# BlueNRG2 register map
Vendor: STMicroelectronics; Series: BlueNRG2; File version: 1.2.1
ARM 32-bit Cortex-M0 Microcontroller based device, CPU clock up to 32MHz
CPU: CM0 r0p0, little endian, no MPU, no FPU, 2 interrupt priority bits
Registers are 32-bit, read-write, reset 0x0 unless marked. A register's access mark holds for its fields unless they carry their own. Offsets are from the block's base; lines under a group give offsets from that group; [hi:lo] are bit positions; {n}, {i} and the like mark numbered series; 'fields as' and 'values as' point back to an identical list; <NAME> marks a mode.

## Memory map
0x10000000 ROM_INFO size 0x800 — ROM information
0x40000000 GPIO size 0x1000 — GPIO Controller
0x40100000 FLASH size 0x1000 — Flash Controller
0x40200000 SYSTEM_CTRL size 0x1000 — System controller
0x40300000 UART size 0x1000
0x40400000 SPI size 0x1000 — Serial peripheral interface
0x40700000 WDG size 0x1000 — Watchdog
0x40800000 ADC size 0x1000
0x40900000 CKGEN_SOC size 0x1000 — Clock Gen SOC
0x40A00000 I2C2 size 0x1000
0x40B00000 I2C1 size 0x1000
0x40C00000 AHBUPCONV size 0x1000 — AHB up/down converter converter
0x40D00000 MFT1 size 0x1000
0x40E00000 MFT2 size 0x1000
0x40F00000 RTC size 0x1000 — Real-Time Counter
0x48000000 BLUE_CTRL size 0x1000 — BLUE Controller
0x48100000 CKGEN_BLE size 0x1000 — Clock Gen BLE
0xA0000000 DMA size 0x8
0xA0000008 DMA_CH0 size 0x10 — DMA channel
0xA000001C DMA_CH1 size 0x10
0xA0000030 DMA_CH2 size 0x10
0xA0000044 DMA_CH3 size 0x10
0xA0000058 DMA_CH4 size 0x10
0xA000006C DMA_CH5 size 0x10
0xA0000080 DMA_CH6 size 0x10
0xA0000094 DMA_CH7 size 0x10
0xB0000000 RNG size 0x1000
0xC0000000 PKA size 0x1000

## Interrupts
0 GPIO — GPIO bus interrupt
1 NVM (FLASH) — Non-volatile memory (Flash) controller interrupt
4 UART — UART interrupt
5 SPI — SPI interrupt
6 BLUE_CTRL — BLUE controller interrupt
7 WDG — Watchdog interrupt
13 ADC — ADC interrupt
14 I2C2 — I2C 2 interrupt
15 I2C1 — I2C 1 interrupt
17 MFT1A (MFT1) — Multi functional timer MFT1 interrupt A
18 MFT1B (MFT1) — Multi functional timer MFT1 interrupt B
19 MFT2A (MFT2) — Multi functional timer MFT2 interrupt A
20 MFT2B (MFT2) — Multi functional timer MFT2 interrupt B
21 RTC — RTC interrupt
22 PKA — PKA interrupt
23 DMA — DMA interrupt

## FLASH — Flash Controller
Base 0x40100000
0x00 COMMAND 16-bit — Commands for the module
0x04 CONFIG 16-bit — Configure the wrapper
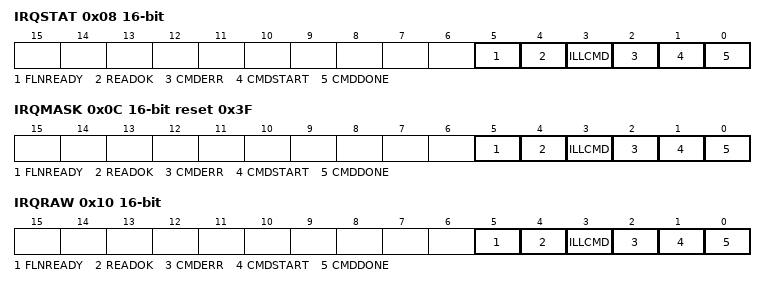
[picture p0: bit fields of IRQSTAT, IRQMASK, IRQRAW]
0x08 IRQSTAT 16-bit — Flash status interrupt (masked)
  [all] fields
    1=IRQ_PENDING; 0=IRQ_NOT_PENDING
  [5] FLNREADY — Flash not ready (sleep). 1: clear the interrupt pending bit.
  [4] READOK — Mass read was OK. 1: clear the interrupt pending bit.
  [3] ILLCMD — Illegal command written. 1: clear the interrupt pending bit.
  [2] CMDERR — Command written while BUSY. 1: clear the interrupt pending bit.
  [1] CMDSTART — Command is started. 1: clear the interrupt pending bit.
  [0] CMDDONE — Command is done. 1: clear the interrupt pending bit.
0x0C IRQMASK 16-bit reset 0x3F — Mask for interrupts
  [all] fields
    1=IRQ_PENDING; 0=IRQ_NOT_PENDING
  [5] FLNREADY — Flash not ready (sleep).
  [4] READOK — Mass read was OK.
  [3] ILLCMD — Illegal command written
  [2] CMDERR — Command written while BUSY
  [1] CMDSTART — Command is started.
  [0] CMDDONE — Command is done.
0x10 IRQRAW 16-bit — Status interrupts (unmasked)
  fields as IRQMASK
0x14 SIZE 16-bit ro — Indicates the size of the main Flash
0x18 ADDRESS — Address for programming Flash, will auto-increment
{0x40+4i} DATA{i} reset 0xFFFFFFFF (i=0..3) — Program cycle data

## Licence text in the file
THIS SOFTWARE IS PROVIDED BY THE COPYRIGHT HOLDERS AND CONTRIBUTORS "AS IS" AND ANY EXPRESS OR IMPLIED WARRANTIES, INCLUDING, BUT NOT LIMITED TO, THE IMPLIED WARRANTIES OF MERCHANTABILITY AND FITNESS FOR A PARTICULAR PURPOSE ARE DISCLAIMED. IN NO EVENT SHALL THE COPYRIGHT HOLDER OR CONTRIBUTORS BE LIABLE FOR ANY DIRECT, INDIRECT, INCIDENTAL, SPECIAL, EXEMPLARY, OR CONSEQUENTIAL DAMAGES (INCLUDING, BUT NOT LIMITED TO, PROCUREMENT OF SUBSTITUTE GOODS OR SERVICES; LOSS OF USE, DATA, OR PROFITS; OR BUSINESS INTERRUPTION) HOWEVER CAUSED AND ON ANY THEORY OF LIABILITY, WHETHER IN CONTRACT, STRICT LIABILITY, OR TORT (INCLUDING NEGLIGENCE OR OTHERWISE) ARISING IN ANY WAY OUT OF THE USE OF THIS SOFTWARE, EVEN IF ADVISED OF THE POSSIBILITY OF SUCH DAMAGE.
